# ISS_BTE register map
Vendor: Texas Instruments
Peripheral module from a debugger description file (folder omap4460).
Registers are 32-bit, access per field, reset 0x0 unless marked. A register's access mark holds for its fields unless they carry their own. Offsets are as the file gives them; lines under a group give offsets from that group; [hi:lo] are bit positions; {n}, {i} and the like mark numbered series; 'fields as' and 'values as' point back to an identical list; <NAME> marks a mode.

## ISS_BTE
0x00 BTE_HL_REVISION ro reset not defined — IP revision identifier (X.Y.R) Used by software to track features, bugs, and compatibility
  [31:0] REVISION — IP revision
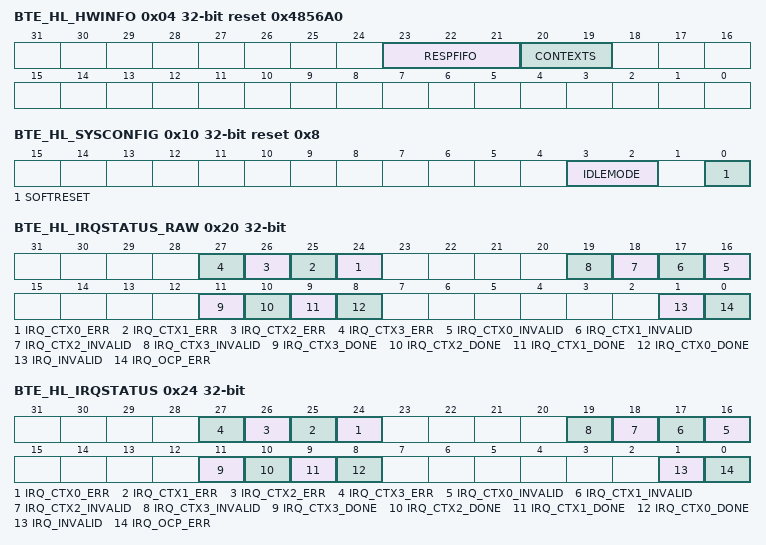
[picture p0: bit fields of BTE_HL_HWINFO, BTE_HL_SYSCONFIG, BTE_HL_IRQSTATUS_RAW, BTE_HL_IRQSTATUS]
0x04 BTE_HL_HWINFO ro reset 0x4856A0 — Information about the hardware configuration of the IP module; that is, typically, the HDL generics (if any) of the module.
  [23:21] RESPFIFO — Response FIFO size
    3=RESPFIFO_3_r (64 x 128 bits); 4=RESPFIFO_4_r (128 x 128 bits); 2=RESPFIFO_2_r (32 x 128 bits); 0=RESPFIFO_0_r (Reserved); 6=RESPFIFO_6_r (Reserved); 1=RESPFIFO_1_r (16 x 128 bits); 7=RESPFIFO_7_r (Reserved); 5=RESPFIFO_5_r (Reserved)
  [20:19] CONTEXTS — Number of contexts
    3=CONTEXTS_3_r (Reserved); 2=CONTEXTS_2_r (8 contexts); 1=CONTEXTS_1_r (4 contexts); 0=CONTEXTS_0_r (2 contexts)
0x10 BTE_HL_SYSCONFIG reset 0x8 — Clock management configuration
  [3:2] IDLEMODE rw — Configuration of the local target state management mode. By definition, target can handle read/write transaction as long as it is out of IDLE state.
    0=An IDLE request is acknowledged unconditionally; 1=An IDLE request is never acknowledged; 3=Reserved. Do not use; 2=Smart-idle mode. Acknowledgment to an IDLE request is given based on the internal activity of the module.
  [0] SOFTRESET rw — Software reset.
    0=SOFTRESET_0_w (No action); 1=SOFTRESET_1_w (Initiate software reset); 1=SOFTRESET_1_r (Reset (software or other) ongoing); 0=SOFTRESET_0_r (Reset done, no pending action)
0x20 BTE_HL_IRQSTATUS_RAW access not given — Per-event raw interrupt status vector Raw status is set even if event is not enabled. Write 1 to set the (raw) status, mostly for debug.
  [n+24] IRQ_CTX{n}_ERR (n=0..3) — Read request received before sufficient data has been prefetched. (access RW W1toSet)
    0=IRQ_CTX{n}_ERR_0_w (No action); 1=IRQ_CTX{n}_ERR_1_w (Set event (debug)); 1=IRQ_CTX{n}_ERR_1_r (Event pending); 0=IRQ_CTX{n}_ERR_0_r (No event pending)
  [n+16] IRQ_CTX{n}_INVALID (n=0..3) — Invalid access. (access RW W1toSet)
    0=IRQ_CTX{n}_INVALID_0_w (No action); 1=IRQ_CTX{n}_INVALID_1_w (Set event (debug)); 1=IRQ_CTX{n}_INVALID_1_r (Event pending); 0=IRQ_CTX{n}_INVALID_0_r (No event pending)
  [11] IRQ_CTX3_DONE — Context has been fully transferred to the TILER (access RW W1toSet)
    0=IRQ_CTX3_DONE_0_w (No action); 1=IRQ_CTX3_DONE_1_w (Set event (debug)); 1=IRQ_CTX3_DONE_1_r (Event pending); 0=IRQ_CTX3_DONE_0_r (No event pending)
  [10] IRQ_CTX2_DONE — Context has been fully transferred to the TILER (access RW W1toSet)
    0=IRQ_CTX2_DONE_0_w (No action); 1=IRQ_CTX2_DONE_1_w (Set event (debug)); 1=IRQ_CTX2_DONE_1_r (Event pending); 0=IRQ_CTX2_DONE_0_r (No event pending)
  [9] IRQ_CTX1_DONE — Context has been fully transferred to the TILER (access RW W1toSet)
    0=IRQ_CTX1_DONE_0_w (No action); 1=IRQ_CTX1_DONE_1_w (Set event (debug)); 1=IRQ_CTX1_DONE_1_r (Event pending); 0=IRQ_CTX1_DONE_0_r (No event pending)
  [8] IRQ_CTX0_DONE — Write mode: Context has been fully transferred to the TILER Read mode: Context prefetch has completed. (access RW W1toSet)
    0=IRQ_CTX0_DONE_0_w (No action); 1=IRQ_CTX0_DONE_1_w (Set event (debug)); 1=IRQ_CTX0_DONE_1_r (Event pending); 0=IRQ_CTX0_DONE_0_r (No event pending)
  [1] IRQ_INVALID — Invalid access to the virtual space (access RW W1toSet)
    0=IRQ_INVALID_0_w (No action); 1=IRQ_INVALID_1_w (Set event (debug)); 1=IRQ_INVALID_1_r (Event pending); 0=IRQ_INVALID_0_r (No event pending)
  [0] IRQ_OCP_ERR — OCP error received from OCP master port. (access RW W1toSet)
    0=IRQ_OCP_ERR_0_w (No action); 1=IRQ_OCP_ERR_1_w (Set event (debug)); 1=IRQ_OCP_ERR_1_r (Event pending); 0=IRQ_OCP_ERR_0_r (No event pending)
0x24 BTE_HL_IRQSTATUS access not given — Per-event 'enabled' interrupt status vector. Enabled status is not set unless event is enabled. Write 1 to clear the status after interrupt has been serviced (raw status gets cleared, that is, even if not enabled).
  [n+24] IRQ_CTX{n}_ERR (n=0..3) — Read request received before sufficient data has been prefetched. (access RW W1toClr)
    0=IRQ_CTX{n}_ERR_0_w (No action); 1=IRQ_CTX{n}_ERR_1_w (Clear (raw) event); 1=IRQ_CTX{n}_ERR_1_r (Event pending); 0=IRQ_CTX{n}_ERR_0_r (No (enabled) event pending)
  [n+16] IRQ_CTX{n}_INVALID (n=0..3) — Invalid access. (access RW W1toClr)
    0=IRQ_CTX{n}_INVALID_0_w (No action); 1=IRQ_CTX{n}_INVALID_1_w (Clear (raw) event); 1=IRQ_CTX{n}_INVALID_1_r (Event pending); 0=IRQ_CTX{n}_INVALID_0_r (No (enabled) event pending)
  [11] IRQ_CTX3_DONE — Context has been fully transferred to the TILER (access RW W1toClr)
    0=IRQ_CTX3_DONE_0_w (No action); 1=IRQ_CTX3_DONE_1_w (Clear (raw) event); 1=IRQ_CTX3_DONE_1_r (Event pending); 0=IRQ_CTX3_DONE_0_r (No (enabled) event pending)
  [10] IRQ_CTX2_DONE — Context has been fully transferred to the TILER (access RW W1toClr)
    0=IRQ_CTX2_DONE_0_w (No action); 1=IRQ_CTX2_DONE_1_w (Clear (raw) event); 1=IRQ_CTX2_DONE_1_r (Event pending); 0=IRQ_CTX2_DONE_0_r (No (enabled) event pending)
  [9] IRQ_CTX1_DONE — Context has been fully transferred to the TILER (access RW W1toClr)
    0=IRQ_CTX1_DONE_0_w (No action); 1=IRQ_CTX1_DONE_1_w (Clear (raw) event); 1=IRQ_CTX1_DONE_1_r (Event pending); 0=IRQ_CTX1_DONE_0_r (No (enabled) event pending)
  [8] IRQ_CTX0_DONE — Write mode: Context has been fully transferred to the TILER Read mode: Context prefetch has completed. (access RW W1toClr)
    0=IRQ_CTX0_DONE_0_w (No action); 1=IRQ_CTX0_DONE_1_w (Clear (raw) event); 1=IRQ_CTX0_DONE_1_r (Event pending); 0=IRQ_CTX0_DONE_0_r (No (enabled) event pending)
  [1] IRQ_INVALID — Invalid access to the virtual space (access RW W1toClr)
    0=IRQ_INVALID_0_w (No action); 1=IRQ_INVALID_1_w (Clear (raw) event); 1=IRQ_INVALID_1_r (Event pending); 0=IRQ_INVALID_0_r (No (enabled) event pending)
  [0] IRQ_OCP_ERR — OCP error received from OCP master port. (access RW W1toClr)
    0=IRQ_OCP_ERR_0_w (No action); 1=IRQ_OCP_ERR_1_w (Clear (raw) event); 1=IRQ_OCP_ERR_1_r (Event pending); 0=IRQ_OCP_ERR_0_r (No (enabled) event pending)
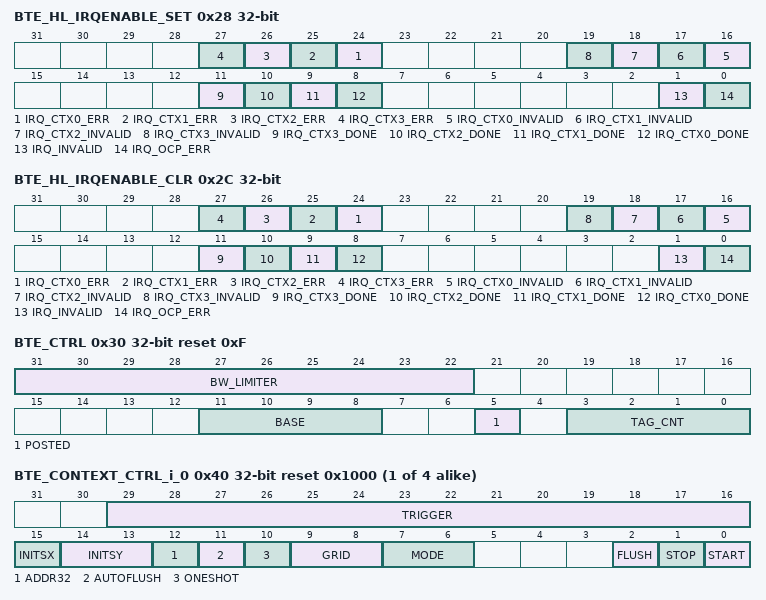
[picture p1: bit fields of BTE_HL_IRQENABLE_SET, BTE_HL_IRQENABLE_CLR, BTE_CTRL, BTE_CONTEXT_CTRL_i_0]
0x28 BTE_HL_IRQENABLE_SET access not given — Per-event interrupt enable bit vector Write 1 to set (enable interrupt). Readout equal to corresponding _CLR register.
  [n+24] IRQ_CTX{n}_ERR (n=0..3) — Read request received before sufficient data has been prefetched. (access RW W1toSet)
    0=IRQ_CTX{n}_ERR_0_w (No action); 1=IRQ_CTX{n}_ERR_1_w (Enable interrupt); 1=IRQ_CTX{n}_ERR_1_r (Interrupt enabled); 0=IRQ_CTX{n}_ERR_0_r (Interrupt disabled (masked))
  [n+16] IRQ_CTX{n}_INVALID (n=0..3) — Invalid access. (access RW W1toSet)
    0=IRQ_CTX{n}_INVALID_0_w (No action); 1=IRQ_CTX{n}_INVALID_1_w (Enable interrupt); 1=IRQ_CTX{n}_INVALID_1_r (Interrupt enabled); 0=IRQ_CTX{n}_INVALID_0_r (Interrupt disabled (masked))
  [11] IRQ_CTX3_DONE — Context has been fully transferred to the TILER (access RW W1toSet)
    0=IRQ_CTX3_DONE_0_w (No action); 1=IRQ_CTX3_DONE_1_w (Enable interrupt); 1=IRQ_CTX3_DONE_1_r (Interrupt enabled); 0=IRQ_CTX3_DONE_0_r (Interrupt disabled (masked))
  [10] IRQ_CTX2_DONE — Context has been fully transferred to the TILER (access RW W1toSet)
    0=IRQ_CTX2_DONE_0_w (No action); 1=IRQ_CTX2_DONE_1_w (Enable interrupt); 1=IRQ_CTX2_DONE_1_r (Interrupt enabled); 0=IRQ_CTX2_DONE_0_r (Interrupt disabled (masked))
  [9] IRQ_CTX1_DONE — Context has been fully transferred to the TILER (access RW W1toSet)
    0=IRQ_CTX1_DONE_0_w (No action); 1=IRQ_CTX1_DONE_1_w (Enable interrupt); 1=IRQ_CTX1_DONE_1_r (Interrupt enabled); 0=IRQ_CTX1_DONE_0_r (Interrupt disabled (masked))
  [8] IRQ_CTX0_DONE — Write mode: Context has been fully transferred to the TILER Read mode: Context prefetch has completed. (access RW W1toSet)
    0=IRQ_CTX0_DONE_0_w (No action); 1=IRQ_CTX0_DONE_1_w (Enable interrupt); 1=IRQ_CTX0_DONE_1_r (Interrupt enabled); 0=IRQ_CTX0_DONE_0_r (Interrupt disabled (masked))
  [1] IRQ_INVALID — Invalid access to the virtual space (access RW W1toSet)
    0=IRQ_INVALID_0_w (No action); 1=IRQ_INVALID_1_w (Enable interrupt); 1=IRQ_INVALID_1_r (Interrupt enabled); 0=IRQ_INVALID_0_r (Interrupt disabled (masked))
  [0] IRQ_OCP_ERR — OCP error received from OCP master port. (access RW W1toSet)
    0=IRQ_OCP_ERR_0_w (No action); 1=IRQ_OCP_ERR_1_w (Enable interrupt); 1=IRQ_OCP_ERR_1_r (Interrupt enabled); 0=IRQ_OCP_ERR_0_r (Interrupt disabled (masked))
0x2C BTE_HL_IRQENABLE_CLR access not given — Per-event interrupt enable bit vector Write 1 to clear (disable interrupt). Readout equal to corresponding _SET register.
  [n+24] IRQ_CTX{n}_ERR (n=0..3) — Read request received before sufficient data has been prefetched. (access RW W1toClr)
    0=IRQ_CTX{n}_ERR_0_w (No action); 1=IRQ_CTX{n}_ERR_1_w (Disable interrupt); 1=IRQ_CTX{n}_ERR_1_r (Interrupt enabled); 0=IRQ_CTX{n}_ERR_0_r (Interrupt disabled (masked))
  [n+16] IRQ_CTX{n}_INVALID (n=0..3) — Invalid access. (access RW W1toClr)
    0=IRQ_CTX{n}_INVALID_0_w (No action); 1=IRQ_CTX{n}_INVALID_1_w (Disable interrupt); 1=IRQ_CTX{n}_INVALID_1_r (Interrupt enabled); 0=IRQ_CTX{n}_INVALID_0_r (Interrupt disabled (masked))
  [11] IRQ_CTX3_DONE — Context has been fully transferred to the TILER (access RW W1toClr)
    0=IRQ_CTX3_DONE_0_w (No action); 1=IRQ_CTX3_DONE_1_w (Disable interrupt); 1=IRQ_CTX3_DONE_1_r (Interrupt enabled); 0=IRQ_CTX3_DONE_0_r (Interrupt disabled (masked))
  [10] IRQ_CTX2_DONE — Context has been fully transferred to the TILER (access RW W1toClr)
    0=IRQ_CTX2_DONE_0_w (No action); 1=IRQ_CTX2_DONE_1_w (Disable interrupt); 1=IRQ_CTX2_DONE_1_r (Interrupt enabled); 0=IRQ_CTX2_DONE_0_r (Interrupt disabled (masked))
  [9] IRQ_CTX1_DONE — Context has been fully transferred to the TILER (access RW W1toClr)
    0=IRQ_CTX1_DONE_0_w (No action); 1=IRQ_CTX1_DONE_1_w (Disable interrupt); 1=IRQ_CTX1_DONE_1_r (Interrupt enabled); 0=IRQ_CTX1_DONE_0_r (Interrupt disabled (masked))
  [8] IRQ_CTX0_DONE — Write mode: Context has been fully transferred to the TILER Read mode: Context prefetch has completed. (access RW W1toClr)
    0=IRQ_CTX0_DONE_0_w (No action); 1=IRQ_CTX0_DONE_1_w (Disable interrupt); 1=IRQ_CTX0_DONE_1_r (Interrupt enabled); 0=IRQ_CTX0_DONE_0_r (Interrupt disabled (masked))
  [1] IRQ_INVALID — Invalid access to the virtual space (access RW W1toClr)
    0=IRQ_INVALID_0_w (No action); 1=IRQ_INVALID_1_w (Disable interrupt); 1=IRQ_INVALID_1_r (Interrupt enabled); 0=IRQ_INVALID_0_r (Interrupt disabled (masked))
  [0] IRQ_OCP_ERR — OCP error received from OCP master port. (access RW W1toClr)
    0=IRQ_OCP_ERR_0_w (No action); 1=IRQ_OCP_ERR_1_w (Disable interrupt); 1=IRQ_OCP_ERR_1_r (Interrupt enabled); 0=IRQ_OCP_ERR_0_r (Interrupt disabled (masked))
0x30 BTE_CTRL reset 0xF — BTE control register
  [31:22] BW_LIMITER rw — Minimum number of OCP cycles between two consecutive buffer flushing or prefetch requests. Used to limit the bandwidth used to fill/empty buffers. 0: Maximum speed. Up to 1 request every 8 cycles (3.2GB @ 200 MHz) 1: Up to 1 request every 9 cycles. 1023: Minimum speed. Up to 1 request every 1031 cycles (24MB @ 200 MHz)
  [11:8] BASE rw — Base address of the virtual space translated by the BTE. Start address = BASE*512MB End address = (BASE+1)*512MB – 1 For example: BASE=3 =&gt; 0x 0 6000 0000 - 0x 0 7FFF FFFF
  [5] POSTED rw — Select among posted and nonposted writes for translated requests.
    0=Use non posted writes; 1=Use posted writes
  [3:0] TAG_CNT rw — BTE could use up to TAG_CNT+1 tags on OCPO. There could only be one outstanding request per tag. TAG_CNT does not control the number of requests it could handle on OCPI. This register is internally shadowed. Modifications are taken into account when there are no outstanding transactions on OCPO. TAG ID 0 to TAG_CNT are used on OCPO.
0x34 BTE_CTRL1 reset 0xF — BTE control register
  [6:0] RESP_FIFO_THR rw — The BTE stops accepting new requests from OCPI (on a clean burst boundary) when the response FIFO contains more than RESP_FIFO_THR words. The reset value is FIFO_SIZE - 16 - 1. FIFO_SIZE = 8 * 2
{0x40+0x20*i} BTE_CONTEXT_CTRL_i_{i} reset 0x1000 (i=0..3) — Context control register
  [29:16] TRIGGER rw — Threshold used to trigger translated requests to OCPO. Unit: words or 16 bytes Valid range: 3 lines + 2 ... 4 lines WRITE: a 2D write is issued to OCPO when the internal buffer level (including masked accesses) is superior or equal to TRIGGER READ: a 2D read is issued to OCPO when the internal buffer level (including masked accesses) is inferior to TRIGGER.
  [15] INITSX rw — Reset value to be used for SX__x. Check the section describing the local buffer management for details.
  [14:13] INITSY rw — Reset value to be used for SY__x. Check the section describing the local buffer management for details. Must be 0 when ONESHOT = 0.
  [12] ADDR32 rw — Controls the value of the OCP address bit 32 to be used for translated accesses
  [11] AUTOFLUSH rw — Controls automatic context flushing when an IDLE request is received
    0=Disabled; 1=Enabled
  [10] ONESHOT rw — Selects one-shot or continuous mode
    0=The context is automatically re-enabled when its end is reached; 1=The context is disabled when the end of a frame has been reached
  [9:8] GRID rw — Grid used to access the TILER
    0=Stride = 16k Subtile = 4x4 bytes Tile = 32x32 bytes; 1=Stride = 8k Subtile = 4x4 bytes Tile = 32x32 bytes; 3=Stride = 16k Subtile = 8x2 bytes Tile = 64x16 bytes; 2=Stride = 32k Subtile = 8x2 bytes Tile = 64x16 bytes
  [7:6] MODE rw — Select the translation mode for the context
    0=Write translation; 1=Read translation; 2=Direct access to local buffer
  [2] FLUSH wo — Flushes all remaining data of the context to the TILER.
    0=FLUSH_0_w (No effect); 1=FLUSH_1_w
  [1] STOP wo — Stops the context on a clean OCP transaction boundary.
    0=STOP_0_w (No effect); 1=STOP_1_w (Stop the context)
  [0] START wo — Resets the contexts internal state and enables the context on a clean OCP transaction boundary.
    0=START_0_w (No effect); 1=START_1_w (Reset + Enable)
{0x44+0x20*i} BTE_CONTEXT_BASE_i_{i} (i=0..3) — Address of the frame buffer in the TILER address space.
  [31:5] ADDR rw — Address
{0x48+0x20*i} BTE_CONTEXT_START_i_{i} (i=0..3) — Top-left corner of the context.
  [15:7] X rw — Address, in 128-byte words
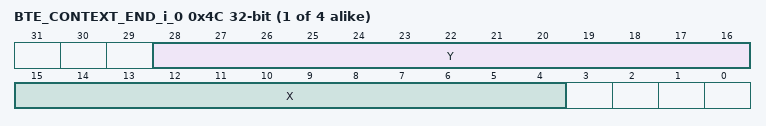
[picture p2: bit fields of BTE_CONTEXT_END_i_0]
{0x4C+0x20*i} BTE_CONTEXT_END_i_{i} (i=0..3) — Bottom-right corner of the context.
  [28:16] Y rw — Last line number for the context (0 corresponds to a context of 1 line) Must be 7 when ONESHOT = 0.
  [15:4] X rw — Address, in 128-bit words, of the last column of the context
